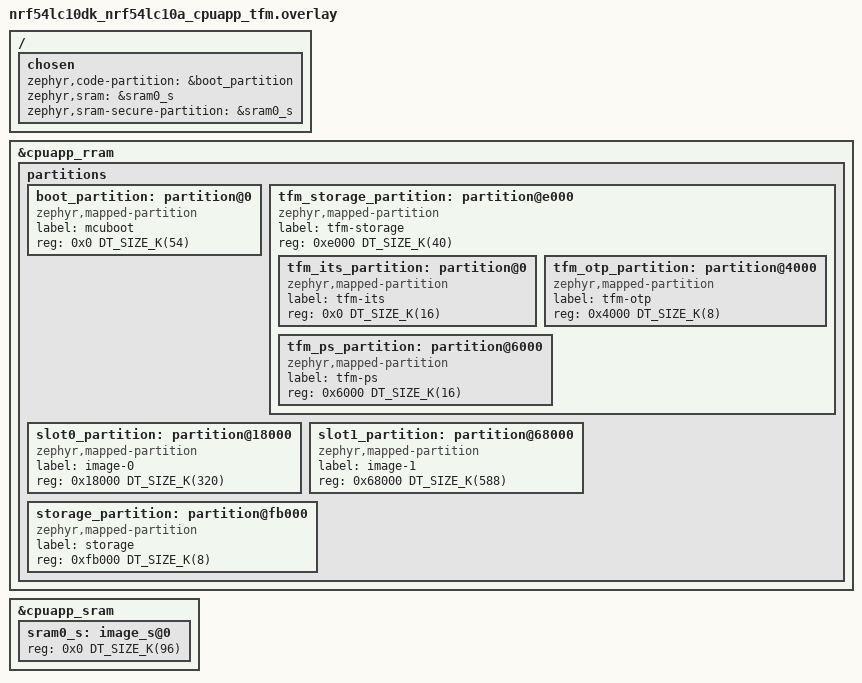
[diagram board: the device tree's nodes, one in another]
/*
 * Copyright (c) 2026 Nordic Semiconductor ASA
 *
 * SPDX-License-Identifier: LicenseRef-Nordic-5-Clause
 */

/delete-node/ &slot1_partition;

/delete-node/ &slot0_partition;
/delete-node/ &storage_partition;

&cpuapp_rram {
	partitions {
		ranges;
		#address-cells = <1>;
		#size-cells = <1>;

		boot_partition: partition@0 {
			compatible = "zephyr,mapped-partition";
			label = "mcuboot";
			reg = <0x0 DT_SIZE_K(54)>;
		};

		tfm_storage_partition: partition@e000 {
			compatible = "zephyr,mapped-partition";
			label = "tfm-storage";
			reg = <0xe000 DT_SIZE_K(40)>;
			ranges = <0x0 0xe000 DT_SIZE_K(40)>;
			#address-cells = <1>;
			#size-cells = <1>;

			tfm_its_partition: partition@0 {
				compatible = "zephyr,mapped-partition";
				label = "tfm-its";
				reg = <0x0 DT_SIZE_K(16)>;
			};

			tfm_otp_partition: partition@4000 {
				compatible = "zephyr,mapped-partition";
				label = "tfm-otp";
				reg = <0x4000 DT_SIZE_K(8)>;
			};

			tfm_ps_partition: partition@6000 {
				compatible = "zephyr,mapped-partition";
				label = "tfm-ps";
				reg = <0x6000 DT_SIZE_K(16)>;
			};
		};

		slot0_partition: partition@18000 {
			compatible = "zephyr,mapped-partition";
			label = "image-0";
			reg = <0x18000 DT_SIZE_K(320)>;
		};

		slot1_partition: partition@68000 {
			compatible = "zephyr,mapped-partition";
			label = "image-1";
			reg = <0x68000 DT_SIZE_K(588)>;
		};

		storage_partition: partition@fb000 {
			compatible = "zephyr,mapped-partition";
			label = "storage";
			reg = <0xfb000 DT_SIZE_K(8)>;
		};
	};
};

&cpuapp_sram {
	sram0_s: image_s@0 {
		reg = <0x0 DT_SIZE_K(96)>;
	};
};

/ {
	chosen {
		zephyr,code-partition = &boot_partition;
		zephyr,sram = &sram0_s;
		zephyr,sram-secure-partition = &sram0_s;
	};
};

#include "../app.overlay"
